# RP2040 register map
Vendor: Raspberry Pi; File version: 0.1
CPU: CM0PLUS r0p1, little endian, MPU, no FPU, VTOR, 2 interrupt priority bits, 26 interrupts
Registers are 32-bit, read-write, reset 0x0 unless marked. A register's access mark holds for its fields unless they carry their own. Offsets are from the block's base; [hi:lo] are bit positions; lines under a group give offsets from that group; {n}, {i} and the like mark numbered series.

## PWM — Simple PWM
Base 0x40050000
{0x0+0x14*i} CH{i} (i=0..7) group — Cluster CH{i}, containing CH*_CC, CH*_CSR, CH*_CTR, CH*_DIV, CH*_TOP
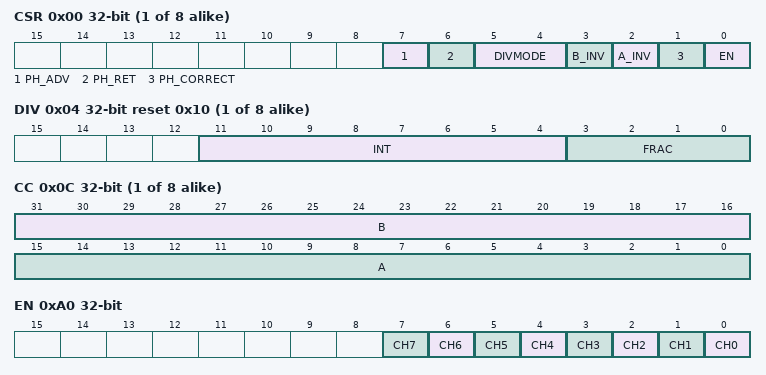
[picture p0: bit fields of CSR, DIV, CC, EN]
  0x00 CSR — Control and status register
    [7] PH_ADV write-clears — Advance the phase of the counter by 1 count, while it is running. Self-clearing. Write a 1, and poll until low. Counter must be running at less than full speed (div_int + div_frac / 16 > 1)
    [6] PH_RET write-clears — Retard the phase of the counter by 1 count, while it is running. Self-clearing. Write a 1, and poll until low. Counter must be running.
    [5:4] DIVMODE
      0=div (Free-running counting at rate dictated by fractional divider); 1=level (Fractional divider operation is gated by the PWM B pin.); 2=rise (Counter advances with each rising edge of the PWM B pin.); 3=fall (Counter advances with each falling edge of the PWM B pin.)
    [3] B_INV — Invert output B
    [2] A_INV — Invert output A
    [1] PH_CORRECT — 1: Enable phase-correct modulation. 0: Trailing-edge
    [0] EN — Enable the PWM channel.
  0x04 DIV reset 0x10 — INT and FRAC form a fixed-point fractional number. Counting rate is system clock frequency divided by this number. Fractional division uses simple 1st-order sigma-delta.
    [11:4] INT, [3:0] FRAC
  0x08 CTR — Direct access to the PWM counter
    [15:0] CTR
  0x0C CC — Counter compare values
    [31:16] B, [15:0] A
  0x10 TOP reset 0xFFFF — Counter wrap value
    [15:0] TOP
0xA0 EN — This register aliases the CSR_EN bits for all channels. Writing to this register allows multiple channels to be enabled or disabled simultaneously, so they can run in perfect sync. For each channel, there is only one physical EN register bit, which can be accessed through here or CHx_CSR.
  [n] CH{n} (n=0..7)
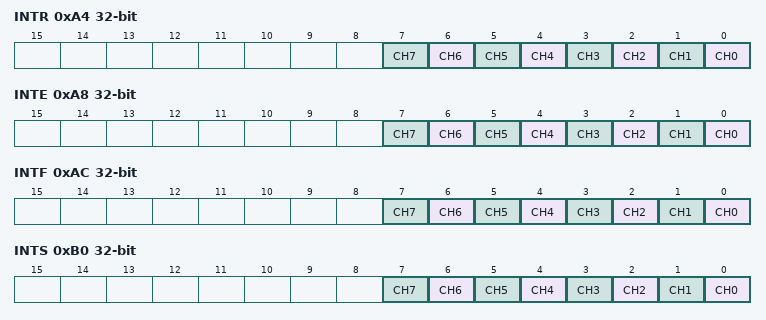
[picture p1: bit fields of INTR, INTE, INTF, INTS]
0xA4 INTR — Raw Interrupts
  [n] CH{n} write-1-clears (n=0..7)
0xA8 INTE — Interrupt Enable
  [n] CH{n} (n=0..7)
0xAC INTF — Interrupt Force
  [n] CH{n} (n=0..7)
0xB0 INTS ro — Interrupt status after masking & forcing
  [n] CH{n} (n=0..7)

## TIMER — Controls time and alarms time is a 64 bit value indicating the time in usec since power-on timeh is the top 32 bits of time & timel is the bottom 32 bits to change time write to timelw before timehw to read time read from timelr before timehr. An alarm is set by setting alarm_enable and writing to the corresponding alarm register. When an alarm is pending, the corresponding alarm_running signal will be high. An alarm can be cancelled before it has finished by clearing the alarm_enable. When an alarm fires, the corresponding alarm_irq is set and alarm_running is cleared. To clear the interrupt write a 1 to the corresponding alarm_irq
Base 0x40054000
0x00 TIMEHW wo — Write to bits 63:32 of time always write timelw before timehw
0x04 TIMELW wo — Write to bits 31:0 of time writes do not get copied to time until timehw is written
0x08 TIMEHR ro — Read from bits 63:32 of time always read timelr before timehr
0x0C TIMELR ro — Read from bits 31:0 of time
{0x10+4i} ALARM{i} (i=0..3) — Arm alarm {i}, and configure the time it will fire. Once armed, the alarm fires when TIMER_ALARM{i} == TIMELR. The alarm will disarm itself once it fires, and can be disarmed early using the ARMED status register.
0x20 ARMED — Indicates the armed/disarmed status of each alarm. A write to the corresponding ALARMx register arms the alarm. Alarms automatically disarm upon firing, but writing ones here will disarm immediately without waiting to fire.
  [3:0] ARMED write-1-clears
0x24 TIMERAWH ro — Raw read from bits 63:32 of time (no side effects)
0x28 TIMERAWL ro — Raw read from bits 31:0 of time (no side effects)
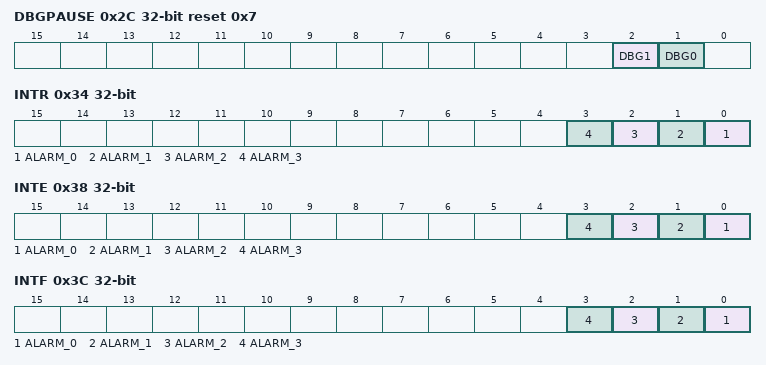
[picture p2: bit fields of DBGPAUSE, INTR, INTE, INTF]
0x2C DBGPAUSE reset 0x7 — Set bits high to enable pause when the corresponding debug ports are active
  [2] DBG1 — Pause when processor 1 is in debug mode
  [1] DBG0 — Pause when processor 0 is in debug mode
0x30 PAUSE — Set high to pause the timer
  [0] PAUSE
0x34 INTR — Raw Interrupts
  [n] ALARM_{n} write-1-clears (n=0..3)
0x38 INTE — Interrupt Enable
  [n] ALARM_{n} (n=0..3)
0x3C INTF — Interrupt Force
  [n] ALARM_{n} (n=0..3)
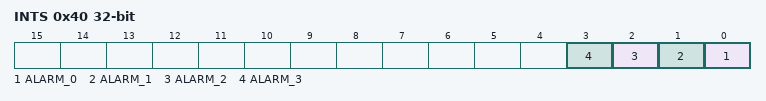
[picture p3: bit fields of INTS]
0x40 INTS ro — Interrupt status after masking & forcing
  [n] ALARM_{n} (n=0..3)

## Notices in the file
Copyright (c) 2020 Raspberry Pi (Trading) Ltd.
SPDX-License-Identifier: BSD-3-Clause
